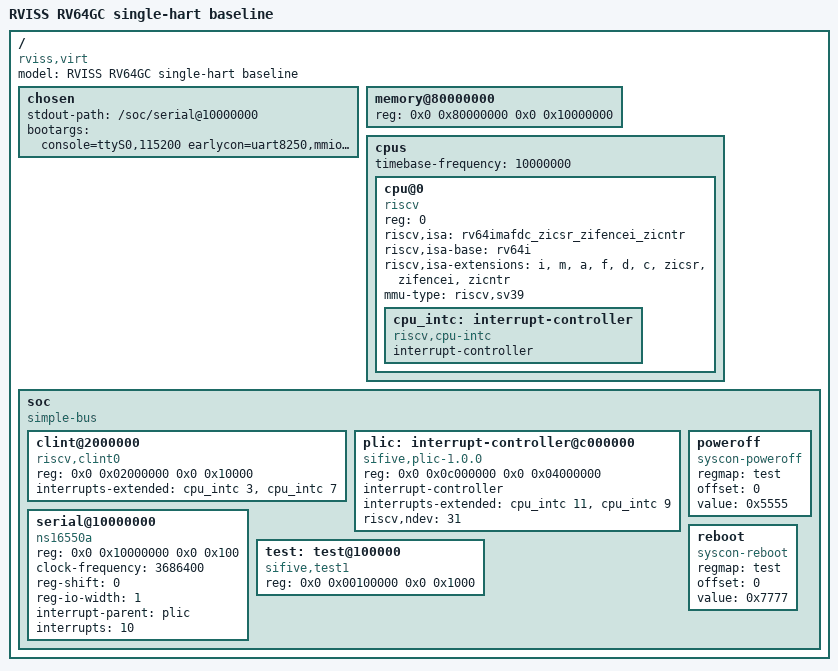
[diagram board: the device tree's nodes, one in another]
/dts-v1/;

/ {
    #address-cells = <2>;
    #size-cells = <2>;
    compatible = "rviss,virt", "riscv-virtio";
    model = "RVISS RV64GC single-hart baseline";

    chosen {
        stdout-path = "/soc/serial@10000000";
        bootargs = "console=ttyS0,115200 earlycon=uart8250,mmio,0x10000000 rdinit=/init loglevel=6";
    };

    memory@80000000 {
        device_type = "memory";
        reg = <0x0 0x80000000 0x0 0x10000000>;
    };

    cpus {
        #address-cells = <1>;
        #size-cells = <0>;
        timebase-frequency = <10000000>;
        cpu@0 {
            device_type = "cpu";
            compatible = "riscv";
            reg = <0>;
            status = "okay";
            riscv,isa = "rv64imafdc_zicsr_zifencei_zicntr";
            riscv,isa-base = "rv64i";
            riscv,isa-extensions = "i", "m", "a", "f", "d", "c",
                                   "zicsr", "zifencei", "zicntr";
            mmu-type = "riscv,sv39";
            cpu_intc: interrupt-controller {
                #interrupt-cells = <1>;
                interrupt-controller;
                compatible = "riscv,cpu-intc";
            };
        };
    };

    soc {
        #address-cells = <2>;
        #size-cells = <2>;
        compatible = "simple-bus";
        ranges;

        clint@2000000 {
            compatible = "riscv,clint0";
            reg = <0x0 0x02000000 0x0 0x10000>;
            interrupts-extended = <&cpu_intc 3 &cpu_intc 7>;
        };

        plic: interrupt-controller@c000000 {
            compatible = "sifive,plic-1.0.0", "riscv,plic0";
            reg = <0x0 0x0c000000 0x0 0x04000000>;
            #address-cells = <0>;
            #interrupt-cells = <1>;
            interrupt-controller;
            interrupts-extended = <&cpu_intc 11 &cpu_intc 9>;
            riscv,ndev = <31>;
        };

        serial@10000000 {
            compatible = "ns16550a";
            reg = <0x0 0x10000000 0x0 0x100>;
            clock-frequency = <3686400>;
            reg-shift = <0>;
            reg-io-width = <1>;
            interrupt-parent = <&plic>;
            interrupts = <10>;
        };

        test: test@100000 {
            compatible = "sifive,test1", "sifive,test0", "syscon";
            reg = <0x0 0x00100000 0x0 0x1000>;
        };

        poweroff {
            compatible = "syscon-poweroff";
            regmap = <&test>;
            offset = <0>;
            value = <0x5555>;
        };

        reboot {
            compatible = "syscon-reboot";
            regmap = <&test>;
            offset = <0>;
            value = <0x7777>;
        };
    };
};
